# renode register map
Vendor: litex
Registers are 32-bit, read-write, reset 0x0 unless marked. A register's access mark holds for its fields unless they carry their own. Offsets are from the block's base; [hi:lo] are bit positions.

## MESSIBLE
Base 0xF000F000
Same registers: MESSIBLE2 0xF0010000
0x00 IN — Write half of the FIFO to send data out the Messible. Writing to this register advances the write pointer automatically.
  [7:0] in
0x04 OUT — Read half of the FIFO to receive data on the Messible. Reading from this register advances the read pointer automatically.
  [7:0] out
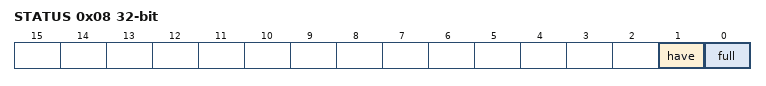
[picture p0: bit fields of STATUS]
0x08 STATUS
  [1] have — `1` if data can be read from the OUT FIFO.
  [0] full — `0` if more data can fit into the IN FIFO.

## TICKTIMER
Base 0xF0011000
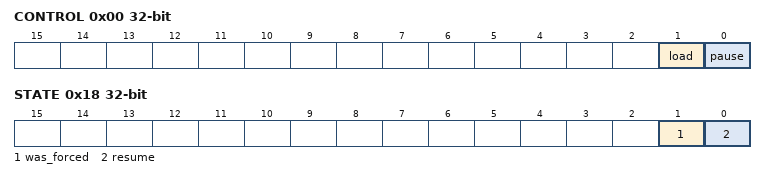
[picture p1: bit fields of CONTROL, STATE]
0x00 CONTROL
  [0] reset — Write a `1` to this bit to reset the count to 0. This bit has priority over all other requests.
0x04 TIME1 — Bits 32-63 of `TICKTIMER_TIME`. Elapsed time in systicks
  [31:0] time
0x08 TIME0 — Bits 0-31 of `TICKTIMER_TIME`.
  [31:0] time
0x0C MSLEEP_TARGET1 — Bits 32-63 of `TICKTIMER_MSLEEP_TARGET`. Target time in 1.0ms ticks
  [31:0] msleep_target
0x10 MSLEEP_TARGET0 — Bits 0-31 of `TICKTIMER_MSLEEP_TARGET`.
  [31:0] msleep_target
0x14 EV_STATUS — This register contains the current raw level of the alarm event trigger. Writes to this register have no effect.
  [0] alarm — Level of the ``alarm`` event
0x18 EV_PENDING — When a alarm event occurs, the corresponding bit will be set in this register. To clear the Event, set the corresponding bit in this register.
  [0] alarm — `1` if a `alarm` event occurred. This Event is **level triggered** when the signal is **high**.
0x1C EV_ENABLE — This register enables the corresponding alarm events. Write a ``0`` to this register to disable individual events.
  [0] alarm — Write a ``1`` to enable the ``alarm`` Event

## SUSRES
Base 0xF0012000
0x00 CONTROL
  [1] load — If paused, write a `1` to this bit to load a resume value to the timer. If not paused, this bit is ignored.
  [0] pause — Write a `1` to this field to request a pause to counting, 0 for free-run. Count pauses on the next tick quanta.
0x04 RESUME_TIME1 — Bits 32-63 of `SUSRES_RESUME_TIME`. Elapsed time to load. Loaded upon writing `1` to the load bit in the control register. This will immediately affect the msleep extension.
  [31:0] resume_time
0x08 RESUME_TIME0 — Bits 0-31 of `SUSRES_RESUME_TIME`.
  [31:0] resume_time
0x0C TIME1 — Bits 32-63 of `SUSRES_TIME`. Cycle-accurate mirror copy of time in systicks, from the TickTimer
  [31:0] time
0x10 TIME0 — Bits 0-31 of `SUSRES_TIME`.
  [31:0] time
0x14 STATUS
  [0] paused — When set, indicates that the counter has been paused
0x18 STATE
  [1] was_forced — Used by the bootloader to indicate to the kernel if the current resume was from a forced suspend (e.g. a timeout happened and a server may be unclean.
  [0] resume — Used to transfer the resume state information from the loader to Xous. If set, indicates we are on the resume half of a suspend/resume.
0x1C POWERDOWN
  [0] powerdown — Write a `1` to force an immediate powerdown. Use with care.
0x20 INTERRUPT
  [0] interrupt — Writing this causes an interrupt to fire. Used by Xous to initiate suspend/resume from an interrupt context.
0x24 EV_STATUS — This register contains the current raw level of the soft_int event trigger. Writes to this register have no effect.
  [0] soft_int — Level of the ``soft_int`` event
0x28 EV_PENDING — When a soft_int event occurs, the corresponding bit will be set in this register. To clear the Event, set the corresponding bit in this register.
  [0] soft_int — `1` if a `soft_int` event occurred. This Event is triggered on a **falling** edge.
0x2C EV_ENABLE — This register enables the corresponding soft_int events. Write a ``0`` to this register to disable individual events.
  [0] soft_int — Write a ``1`` to enable the ``soft_int`` Event

## POWER
Base 0xF0013000
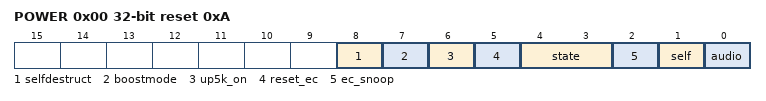
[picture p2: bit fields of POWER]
0x00 POWER reset 0xA
  [8] selfdestruct — Set this bit to clear BBRAM AES key (if used) and cut power in an annoying-to- reset fashion
  [7] boostmode — Writing a `1` causes the USB port to source 5V. To be active only when playing the host role.
  [6] up5k_on — Writing a `1` pulses the UP5K domain to turn on
  [5] reset_ec — Writing a `1` forces EC into reset. Requires write of `0` to release reset.
  [4:3] state — Current SoC power state. 0x=off or not ready, 10=on and safe to shutdown, 11=on and not safe to shut down, resets to 01 to allow extSRAM access immediately during init
  [2] ec_snoop — Writing `1` allows the insecure EC to snoop a couple keyboard pads for wakeup key sequence recognition
  [1] self — Writing `1` forces self power-on (overrides the EC's ability to power me down)
  [0] audio — Write `1` to power on the audio subsystem
0x04 VIBE — Vibration motor configuration register
  [0] vibe — Turn on vibration motor
0x08 EV_STATUS — USB attach event
  [0] usb_attach — Level of the ``usb_attach`` event
0x0C EV_PENDING — USB attach event
  [0] usb_attach
0x10 EV_ENABLE — USB attach event
  [0] usb_attach — Write a ``1`` to enable the ``usb_attach`` Event
